# BE-U1000 register map
Vendor: BAIKAL ELECTRONICS, JSC; File version: 1.0
CPU: RISC-V r0p0, little endian, no MPU, no FPU, 3 interrupt priority bits
Registers are 32-bit, read-write, reset 0x0 unless marked. A register's access mark holds for its fields unless they carry their own. Offsets are from the block's base; [hi:lo] are bit positions; {n}, {i} and the like mark numbered series.

## UART0 — Universal Asynchronous Receiver/Transmitter
Base 0x11001000
Same registers: UART1 0x11002000, UART2 0x11003000, UART3 0x13001000, UART4 0x13002000, UART5 0x13003000, UART6 0x14009000, UART7 0x1400A000
0x00 RBR — Receive Buffer Register
0x00 RBR_8BIT — Receive Buffer Register
  [7:0] RBR — Received data (8-bit mode)
0x00 RBR_9BIT — Receive Buffer Register
  [8:0] RBR — Received data (9-bit mode)
0x00 THR — Transmit Holding Register
0x00 THR_8BIT — Transmit Holding Register
  [7:0] THR — Data to be transmitted (8-bit mode)
0x00 THR_9BIT — Transmit Holding Register
  [8:0] THR — Data to be transmitted (9-bit mode)
0x00 DLL — Divisor Latch (Low)
  [7:0] DLL — Lower 8 bits of the baudrate divisor
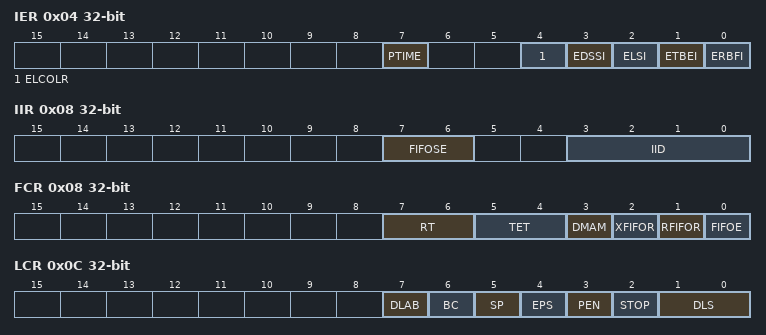
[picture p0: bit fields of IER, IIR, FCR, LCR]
0x04 IER — Interrupt Enable Register
  [7] PTIME — Programmable THRE interrupt mode enable
    0=DISABLE (Disable Programmable THRE Interrupt Mode); 1=ENABLE (Enable Programmable THRE Interrupt Mode)
  [4] ELCOLR — The method for clearing the status in the LSR register
    0=DISABLE (LSR status bits are cleared either on reading Rx FIFO (RBR read) or on reading LSR register); 1=ENABLE (LSR status bits are cleared only on reading LSR register)
  [3] EDSSI — Enable modem status interrupt
    0=DISABLE (Disable Modem Status interrupt); 1=ENABLE (Enable Modem Status interrupt)
  [2] ELSI — Enable receiver line status interrupt
    0=DISABLE (Disable Receiver Line Status interrupt); 1=ENABLE (Enable Receiver Line Status interrupt)
  [1] ETBEI — Enable transmit holding register empty interrupt
    0=DISABLE (Disable Transmit Holding Register Empty interrupt); 1=ENABLE (Enable Transmit Holding Register Empty interrupt)
  [0] ERBFI — Enable received data available interrupt
    0=DISABLE (Disable Received Data Available interrupt); 1=ENABLE (Enable Received Data Available interrupt)
0x04 DLH — Divisor Latch High
  [7:0] DLH — Upper 8 bits of the baudrate divisor
0x08 IIR — Interrupt Identification Register
  [7:6] FIFOSE — FIFOs enabled
    0=DISABLE (FIFOs are disabled); 3=ENABLE (FIFOs are enabled)
  [3:0] IID — Interrupt ID
    0=MODEM_STATUS; 1=NO_INT_PENDING (No interrupt pending); 2=THR_EMPTY; 4=RX_DATA_AVAILABLE (Received data available); 6=RX_LINE_STATUS (Receiver line status); 7=BUSY_DETECT; 12=CHAR_TIMEOUT (Character timeout)
0x08 FCR — FIFO Control Register
  [7:6] RT — RX FIFO trigger
    0=FIFO_CHAR_1 (1 character in FIFO); 1=FIFO_QUARTER_FULL (FIFO 1/4 full); 2=FIFO_HALF_FULL (FIFO 1/2 full); 3=FIFO_FULL_2 (FIFO 2 less than full)
  [5:4] TET — TX FIFO empty trigger
    0=FIFO_EMPTY; 1=FIFO_CHAR_2 (2 characters in FIFO); 2=FIFO_QUARTER_FULL (FIFO 1/4 full); 3=FIFO_HALF_FULL (FIFO 1/2 full)
  [3] DMAM — DMA mode
    0=MODE0 (DMA Mode 0); 1=MODE1 (DMA Mode 1)
  [2] XFIFOR — TX FIFO reset
    0=DISABLE; 1=ENABLE
  [1] RFIFOR — RX FIFO reset
    0=DISABLE; 1=ENABLE
  [0] FIFOE — FIFO enable
    0=DISABLE (FIFO disabled); 1=ENABLE (FIFO enabled)
0x0C LCR — Line Control Register
  [7] DLAB — Divisor latch access
    0=DISABLE (Divisor Latch is writable only when UART not busy); 1=ENABLE (Divisor Latch is always readable and writable)
  [6] BC — Break control
    0=DISABLE (Serial output is released for data transmission); 1=ENABLE (Serial output is forced to spacing state)
  [5] SP — Stick parity
    0=DISABLE (Stick parity disabled); 1=ENABLE (Stick parity enabled)
  [4] EPS — Even parity select
    0=ODD (Odd parity); 1=EVEN (Even parity)
  [3] PEN — Parity enable
    0=DISABLE (Disable parity); 1=ENABLE (Enable parity)
  [2] STOP — Number of stop bits
    0=1BIT (1 stop bit); 1=1_5BIT_OR_2BIT (1.5 stop bits when DLS is 0, otherwise 2 stop bits)
  [1:0] DLS — Data length select
    {v}=CHAR_{v+5}BITS ({v+5} data bits per character) (v=0..3)
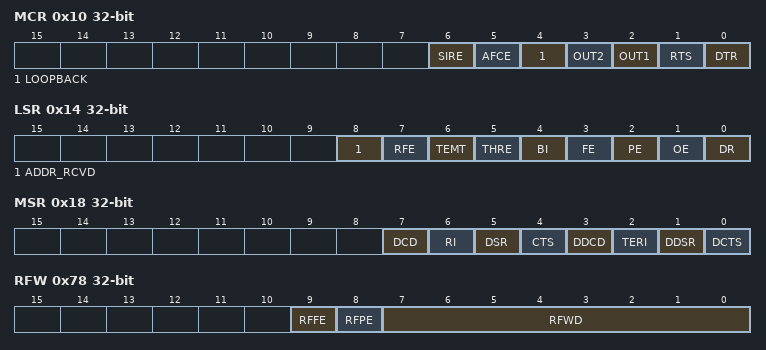
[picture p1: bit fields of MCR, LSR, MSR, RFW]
0x10 MCR — Modem Control Register
  [all] fields
    0=DISABLE; 1=ENABLE
  [6] SIRE — SIR mode enable
  [5] AFCE — Auto flow control enable
  [4] LOOPBACK — Loopback mode
  [3] OUT2 — OUT2 control
  [2] OUT1 — OUT1 control
  [1] RTS — Request to send
  [0] DTR — Data terminal ready
0x14 LSR — Line Status Register
  [all] fields
    0=DISABLE; 1=ENABLE
  [8] ADDR_RCVD — Address received
  [7] RFE — Receiver FIFO error
  [6] TEMT — Transmitter empty
  [5] THRE — Transmit holding register empty
  [4] BI — Break interrupt
  [3] FE — Framing error
  [2] PE — Parity error
  [1] OE — Overrun error
  [0] DR — Data ready
0x18 MSR — Modem Status Register
  [all] fields
    0=DISABLE; 1=ENABLE
  [7] DCD — Data carrier detect
  [6] RI — Ring indicator
  [5] DSR — Data set ready
  [4] CTS — Clear to send
  [3] DDCD — Delta data carrier detect
  [2] TERI — Trailing edge of ring indicator
  [1] DDSR — Delta data set ready
  [0] DCTS — Delta clear to send
0x1C SCR — Scratchpad Register
  [7:0] SCR — Temporary storage space
{0x30+4i} SRBR[{i}] (i=0..15) — Shadow Receive Buffer Register
{0x30+4i} SRBR_8BIT[{i}] (i=0..15) — Shadow Receive Buffer Register
  [7:0] SRBR — Received data (8-bit mode)
{0x30+4i} SRBR_9BIT[{i}] (i=0..15) — Shadow Receive Buffer Register
  [8:0] SRBR — Received data (9-bit mode)
{0x30+4i} STHR[{i}] (i=0..15) — Shadow Transmit Holding Register
{0x30+4i} STHR_8BIT[{i}] (i=0..15) — Shadow Transmit Holding Register
  [7:0] STHR — Data to be transmitted (8-bit mode)
{0x30+4i} STHR_9BIT[{i}] (i=0..15) — Shadow Transmit Holding Register
  [8:0] STHR — Data to be transmitted (9-bit mode)
0x70 FAR — FIFO Access Register
  [0] FAR — FIFO access mode enable
    0=DISABLE; 1=ENABLE
0x74 TFR — Transmit FIFO Read
  [7:0] TFR — TX FIFO read data
0x78 RFW — Receive FIFO Write
  [9] RFFE — RX FIFO framing error
    0=DISABLE; 1=ENABLE
  [8] RFPE — RX FIFO parity error
    0=DISABLE; 1=ENABLE
  [7:0] RFWD — RX FIFO write data
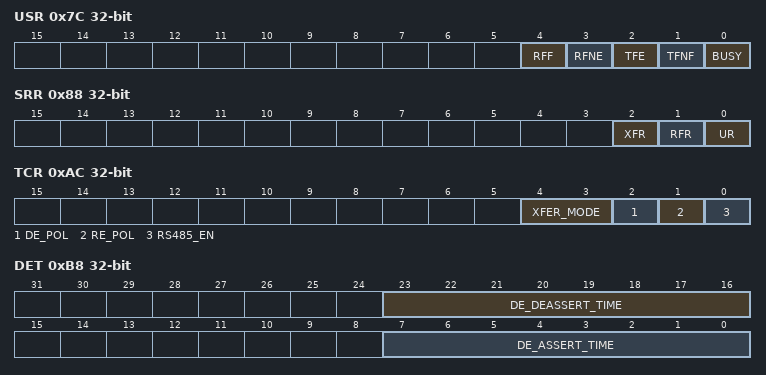
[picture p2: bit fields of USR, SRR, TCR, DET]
0x7C USR — UART Status Register
  [all] fields
    0=DISABLE; 1=ENABLE
  [4] RFF — RX FIFO full
  [3] RFNE — RX FIFO not empty
  [2] TFE — TX FIFO empty
  [1] TFNF — TX FIFO not full
  [0] BUSY — UART busy
0x80 TFL — Transmit FIFO Level
  [4:0] TFL — TX FIFO level
0x84 RFL — Receive FIFO Level
  [4:0] RFL — RX FIFO level
0x88 SRR — Software Reset Register
  [all] fields
    0=DISABLE; 1=ENABLE
  [2] XFR — TX FIFO reset
  [1] RFR — RX FIFO reset
  [0] UR — UART reset
0x8C SRTS — Shadow Request to Send
  [0] SRTS — Shadow request to send
    0=DISABLE; 1=ENABLE
0x90 SBCR — Shadow Break Control Register
  [0] SBCB — Shadow break control
    0=DISABLE; 1=ENABLE
0x94 SDMAM — Shadow DMA Mode Register
  [0] SDMAM — Shadow DMA mode
    0=DISABLE; 1=ENABLE
0x98 SFE — Shadow FIFO Enable Register
  [0] SFE — Shadow FIFO enable
    0=DISABLE; 1=ENABLE
0x9C SRT — Shadow RCVR Trigger Register
  [1:0] SRT — Shadow RX FIFO trigger
    0=UART_SRT_FIFO_CHAR_1 (1 character in FIFO); 1=UART_SRT_FIFO_QUARTER_FULL (FIFO 1/4 full); 2=UART_SRT_FIFO_HALF_FULL (FIFO 1/2 full); 3=UART_SRT_FIFO_FULL_2 (FIFO 2 less than full)
0xA0 STET — Shadow TX Empty Trigger Register
  [1:0] STET — Shadow TX FIFO empty trigger
    0=UART_STET_FIFO_EMPTY (FIFO empty); 1=UART_STET_FIFO_CHAR_2 (2 characters in FIFO); 2=UART_STET_FIFO_QUARTER_FULL (FIFO 1/4 full); 3=UART_STET_FIFO_HALF_FULL (FIFO 1/2 full)
0xA4 HTX — Halt TX
  [0] HTX
    0=DISABLE; 1=ENABLE
0xA8 DMASA — DMA Software Acknowledge Register
  [0] DMASA — DMA software acknowledge
    0=DISABLE; 1=ENABLE
0xAC TCR — Transceiver Control Register
  [4:3] XFER_MODE — Transfer mode
    0=UART_TCR_XFER_MODE0 (Mode 0); 1=UART_TCR_XFER_MODE1 (Mode 1); 2=UART_TCR_XFER_MODE2 (Mode 2)
  [2] DE_POL — Driver enable polarity
    0=DISABLE; 1=ENABLE
  [1] RE_POL — Receiver enable polarity
    0=DISABLE; 1=ENABLE
  [0] RS485_EN — RS485 transfer enable
    0=DISABLE; 1=ENABLE
0xB0 DE_EN — Driver Output Enable Register
  [0] DE_EN — Driver enable
    0=DISABLE; 1=ENABLE
0xB4 RE_EN — Receiver Output Enable Register
  [0] RE_EN — Receiver enable
    0=DISABLE; 1=ENABLE
0xB8 DET — Driver Output Enable Timing Register
  [23:16] DE_DEASSERT_TIME — Driver enable deassertion time
  [7:0] DE_ASSERT_TIME — Driver enable assertion time
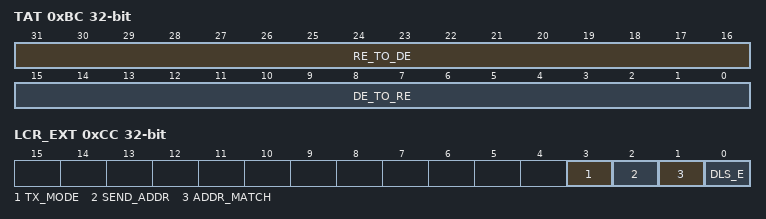
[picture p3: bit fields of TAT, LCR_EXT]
0xBC TAT — TurnAround Timing Register
  [31:16] RE_TO_DE — Receiver enable to driver enable turnaround time
  [15:0] DE_TO_RE — Driver enable to receiver enable turnaround time
0xC0 DLF — Divisor Latch Fraction Register
  [3:0] DLF — Fractional part of baudrate divisor
0xC4 RAR — Receive Address Register
  [7:0] RAR — Receive address
0xC8 TAR — Transmit Address Register
  [7:0] TAR — Transmit address
0xCC LCR_EXT — Line Extended Control Register
  [all] fields
    0=DISABLE; 1=ENABLE
  [3] TX_MODE — Transmit mode control
  [2] SEND_ADDR — Send address control
  [1] ADDR_MATCH — Address match mode
  [0] DLS_E — Enable 9-bit data for transmit and receive transfers
0xD4 REG_TIMEOUT_RST — Register Timeout Counter Reset Value
  [7:0] REG_TIMEOUT_RST — reset value of REG_TIMEOUT register
0xF4 CPR — Component Parameter Register
0xF8 UCV — UART Component Version
  [31:0] UCV — UART component version
0xFC CTR — Component Type Register
  [31:0] CTR — UART component type
